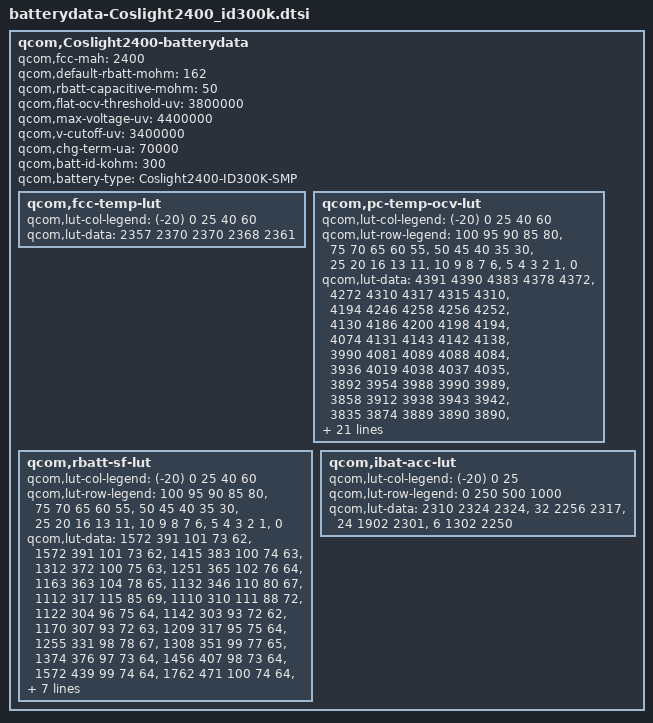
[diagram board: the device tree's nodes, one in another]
/* Copyright (c) 2013-2014  The Linux Foundation. All rights reserved.
 *
 * This program is free software; you can redistribute it and/or modify
 * it under the terms of the GNU General Public License version 2 and
 * only version 2 as published by the Free Software Foundation.
 *
 * This program is distributed in the hope that it will be useful,
 * but WITHOUT ANY WARRANTY; without even the implied warranty of
 * MERCHANTABILITY or FITNESS FOR A PARTICULAR PURPOSE.  See the
 * GNU General Public License for more details.
 */


qcom,Coslight2400-batterydata {


	qcom,fcc-mah = <2400>;
	qcom,default-rbatt-mohm = <162>;
	qcom,rbatt-capacitive-mohm = <50>;
	qcom,flat-ocv-threshold-uv = <3800000>;
	qcom,max-voltage-uv = <4400000>;
	qcom,v-cutoff-uv = <3400000>;
	qcom,chg-term-ua = <70000>;
	qcom,batt-id-kohm = <300>;
	qcom,battery-type = "Coslight2400-ID300K-SMP";

	qcom,fcc-temp-lut {
		qcom,lut-col-legend = <(-20) 0 25 40 60>;
		qcom,lut-data = <2357 2370 2370 2368 2361>;  
	};

	qcom,pc-temp-ocv-lut {
		qcom,lut-col-legend = <(-20) 0 25 40 60>;
		qcom,lut-row-legend = <100 95 90 85 80>,
				<75 70 65 60 55>,
				<50 45 40 35 30>,
				<25 20 16 13 11>,
				<10 9 8 7 6>,
				<5 4 3 2 1>,
				<0>;
		qcom,lut-data =	 <4391 4390 4383 4378 4372>, 
				 <4272 4310 4317 4315 4310>, 
				 <4194 4246 4258 4256 4252>, 
				 <4130 4186 4200 4198 4194>, 
				 <4074 4131 4143 4142 4138>, 
				 <3990 4081 4089 4088 4084>, 
				 <3936 4019 4038 4037 4035>, 
				 <3892 3954 3988 3990 3989>, 
				 <3858 3912 3938 3943 3942>, 
				 <3835 3874 3889 3890 3890>, 
				 <3817 3842 3855 3856 3856>, 
				 <3800 3816 3829 3830 3830>, 
				 <3785 3798 3808 3809 3808>, 
				 <3770 3784 3790 3792 3790>, 
				 <3756 3772 3773 3771 3765>, 
				 <3740 3758 3755 3748 3737>, 
				 <3722 3740 3736 3727 3715>, 
				 <3704 3720 3716 3708 3694>, 
				 <3688 3704 3698 3690 3678>, 
				 <3672 3696 3688 3682 3670>, 
				 <3664 3692 3686 3680 3669>, 
				 <3654 3688 3684 3678 3667>, 
				 <3640 3684 3682 3676 3665>, 
				 <3624 3677 3678 3672 3660>, 
				 <3604 3664 3666 3660 3644>, 
				 <3577 3638 3638 3630 3608>, 
				 <3540 3594 3591 3583 3562>, 
				 <3489 3534 3530 3522 3500>, 
				 <3410 3450 3448 3442 3420>, 
				 <3279 3326 3334 3319 3290>, 
				 <3016 3036 3030 3000 3000>;


	};

	qcom,rbatt-sf-lut {
		qcom,lut-col-legend = <(-20) 0 25 40 60>;
		qcom,lut-row-legend = <100 95 90 85 80>,
				<75 70 65 60 55>,
				<50 45 40 35 30>,
				<25 20 16 13 11>,
				<10 9 8 7 6>,
				<5 4 3 2 1>,
				<0>;
		qcom,lut-data =  <1572 391 101 73 62>, 
				 <1572 391 101 73 62>, 
				 <1415 383 100 74 63>, 
				 <1312 372 100 75 63>, 
				 <1251 365 102 76 64>, 
				 <1163 363 104 78 65>, 
				 <1132 346 110 80 67>, 
				 <1112 317 115 85 69>, 
				 <1110 310 111 88 72>, 
				 <1122 304 96 75 64>, 
				 <1142 303 93 72 62>, 
				 <1170 307 93 72 63>, 
				 <1209 317 95 75 64>, 
				 <1255 331 98 78 67>, 
				 <1308 351 99 77 65>, 
				 <1374 376 97 73 64>, 
				 <1456 407 98 73 64>, 
				 <1572 439 99 74 64>, 
				 <1762 471 100 74 64>, 
				 <1949 499 101 73 64>, 
				 <2031 510 102 75 65>, 
				 <2057 520 103 77 67>, 
				 <2161 530 106 78 68>, 
				 <2335 557 109 80 70>, 
				 <2656 587 110 80 68>, 
				 <3064 616 109 77 65>, 
				 <3633 660 110 78 67>, 
				 <4475 727 116 80 69>, 
				 <5892 822 127 87 77>, 
				 <11677 1024 157 115 105>, 
				 <23353 2048 314 230 210>;
	};


	qcom,ibat-acc-lut {
		qcom,lut-col-legend = <(-20) 0 25>;
		qcom,lut-row-legend = <0 250 500 1000>;
		qcom,lut-data = <2310 2324 2324>,
				<32 2256 2317>,
				<24 1902 2301>,
				<6 1302 2250>;						
	};


};
